# ICR_MPU register map
Vendor: Texas Instruments
Peripheral module from a debugger description file (folder omap4430).
Registers are 32-bit, read-only, reset 0x0 unless marked. A register's access mark holds for its fields unless they carry their own. Offsets are as the file gives them; lines under a group give offsets from that group; [hi:lo] are bit positions; {n}, {i} and the like mark numbered series; 'fields as' and 'values as' point back to an identical list; <NAME> marks a mode.

## ICR_MPU
0x00 ICR_REVISION reset not defined — This register contains the IP revision code.
  [31:0] REVISION — IP Revision
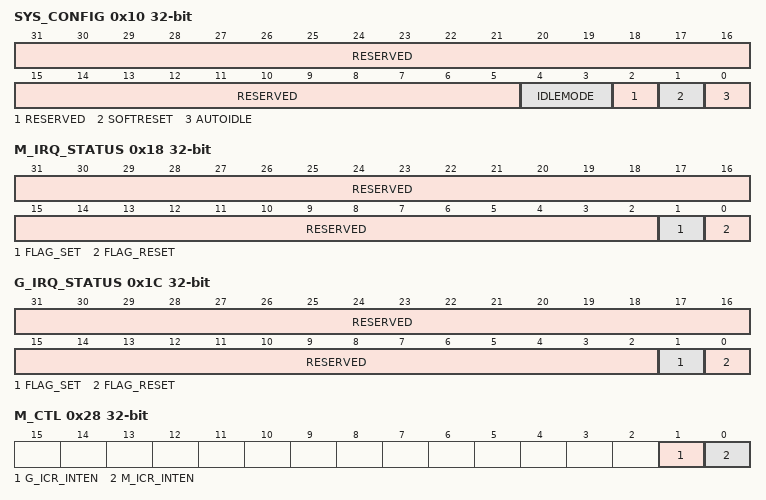
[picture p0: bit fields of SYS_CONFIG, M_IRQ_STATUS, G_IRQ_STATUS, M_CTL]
0x10 SYS_CONFIG access per field — This register allows controlling various parameters of the OCP interface.
  [31:5] RESERVED ro — Read returns 0
  [4:3] IDLEMODE rw — Slave interface power management, req/ack control
    0=Force-idle; 1=No-idle; 2=Smart-idle
  [2] RESERVED ro — Read returns 0
  [1] SOFTRESET rw — Software reset. Set this bit to 1 to trigger a module reset. The bit is automatically reset by the hardware. During reads, it always return 0.0: Normal mode1: The module is reset
  [0] AUTOIDLE rw — Internal OCP clock gating0: OCP clock is free running1: Automatic OCP clock gating strategy is applied based on the OCP interface activity
0x14 SYS_STATUS — This register provides status information about the module, excluding the interrupt status information.
  [0] RESETDONE — Internal reset monitoring0: Internal module reset ongoing1: Reset completed
    1=RESETDONE_1_r (Reset completed); 0=RESETDONE_0_r (Internal module reset in ongoing)
0x18 M_IRQ_STATUS access per field — The interrupt status register regroups all the status of the module internal events that can generate an interrupt - Write 1 to a given bit resets this bit.
  [31:2] RESERVED ro — Reads returns 0
  [1] FLAG_SET rw — Flag has been set inG_ICR register.
    0=FLAG_SET_0_w (Received command (Rx path) status bit unchanged); 1=FLAG_SET_1_w (Received command (Rx path) status bit is reset); 1=FLAG_SET_1_r (Received command (Rx path) is true ('pending')); 0=FLAG_SET_0_r (Received command (Rx path) false)
  [0] FLAG_RESET rw — Flag has been reset inM_ICR register.
    0=FLAG_RESET_0_w (Received command (Rx path) status bit unchanged); 1=FLAG_RESET_1_w (Received command (Rx path) status bit is reset); 1=FLAG_RESET_1_r (Received command (Rx path) is true ('pending')); 0=FLAG_RESET_0_r (Received command (Rx path) false)
0x1C G_IRQ_STATUS access not given — The interrupt status register regroups all the status of the module internal events that can generate an interrupt - Write 1 to a given bit resets this bit.
  [31:2] RESERVED ro — Reads returns 0
  [1] FLAG_SET — Flag has been set inM_ICR register. (access RW W1toClr)
    values as M_IRQ_STATUS.FLAG_SET
  [0] FLAG_RESET — Flag has been reset inG_ICR register. (access RW W1toClr)
    values as M_IRQ_STATUS.FLAG_RESET
0x20 M_ICR access not given — Flags are used to notify an event to the other subsystem. The meaning of each flag is software dependent.
  [31:0] FLAGS — Meaning is software dependent. (access RW W1toClr)
0x24 G_ICR access not given — Flags are used to notify an event to the other subsystem. The meaning of each flag is software dependent.
  [31:0] FLAGS — Meaning is software dependent. (access RW W1toSet)
0x28 M_CTL — Enables interrupts to subsystems.
  [1] G_ICR_INTEN — Enable interrupt to MPU-S0: No interrupt is generated1: An interrupt is generated when Modem-S sets a flag to MPU-S
  [0] M_ICR_INTEN — Enable interrupt to MPU-S0: No interrupt is generated1: An interrupt is generated when Modem-S resets a flag set by MPU-S
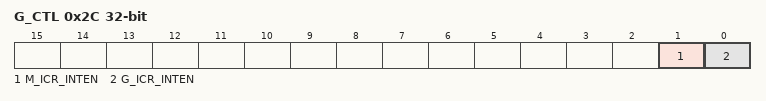
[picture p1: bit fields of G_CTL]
0x2C G_CTL rw — Enables interrupts to subsystems.
  [1] M_ICR_INTEN — Enable interrupt to Modem-S0: No interrupt is generated1: An interrupt is generated when MPU-S sets a flag to Modem-S
  [0] G_ICR_INTEN — Enable interrupt to Modem-S0: No interrupt is generated1: An interrupt is generated when MPU-S resets a flag set by Modem-S
